VERSION ""

NS_ :

BS_:

BU_: VCU INV BMS ABS HVAC IVI GW

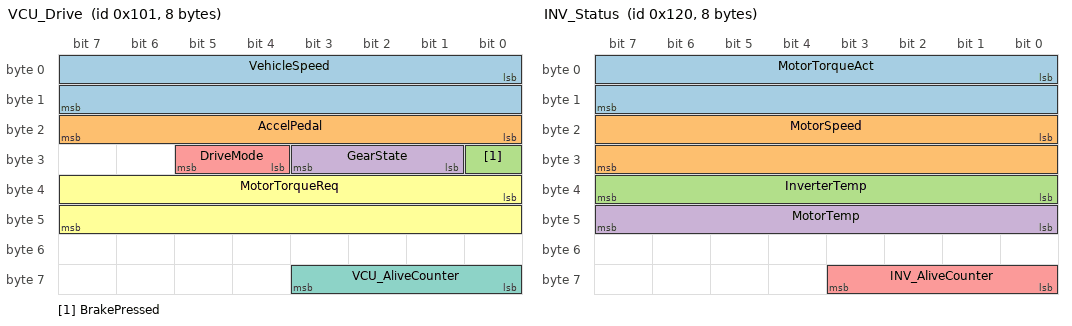
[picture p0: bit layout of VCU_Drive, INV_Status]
BO_ 257 VCU_Drive: 8 VCU
 SG_ VehicleSpeed : 0|16@1+ (0.01,0) [0|300] "km/h" GW,IVI
 SG_ AccelPedal : 16|8@1+ (0.4,0) [0|100] "%" GW
 SG_ BrakePressed : 24|1@1+ (1,0) [0|1] "" GW
 SG_ GearState : 25|3@1+ (1,0) [0|3] "" GW,IVI
 SG_ DriveMode : 28|2@1+ (1,0) [0|3] "" GW
 SG_ MotorTorqueReq : 32|16@1- (0.1,0) [-1000|1000] "Nm" INV
 SG_ VCU_AliveCounter : 56|4@1+ (1,0) [0|15] "" GW

BO_ 288 INV_Status: 8 INV
 SG_ MotorTorqueAct : 0|16@1- (0.1,0) [-1000|1000] "Nm" VCU
 SG_ MotorSpeed : 16|16@1- (1,0) [-20000|20000] "rpm" VCU
 SG_ InverterTemp : 32|8@1+ (1,-40) [-40|150] "degC" VCU
 SG_ MotorTemp : 40|8@1+ (1,-40) [-40|180] "degC" VCU
 SG_ INV_AliveCounter : 56|4@1+ (1,0) [0|15] "" VCU

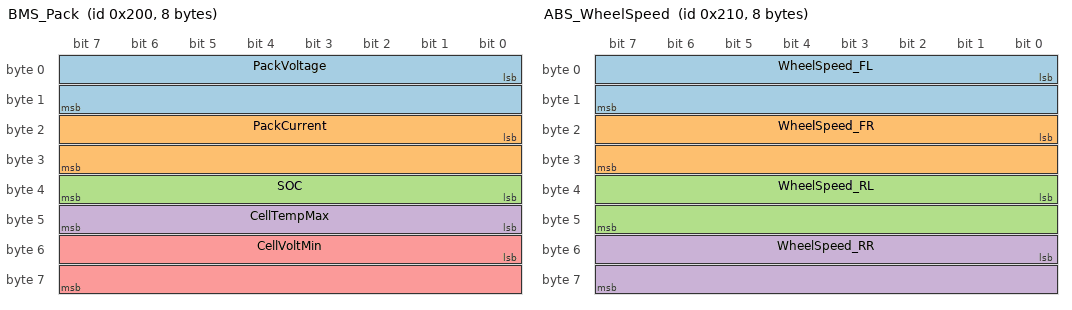
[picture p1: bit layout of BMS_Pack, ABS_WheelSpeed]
BO_ 512 BMS_Pack: 8 BMS
 SG_ PackVoltage : 0|16@1+ (0.1,0) [0|1000] "V" VCU
 SG_ PackCurrent : 16|16@1- (0.1,0) [-1500|1500] "A" VCU
 SG_ SOC : 32|8@1+ (0.5,0) [0|100] "%" VCU,IVI
 SG_ CellTempMax : 40|8@1+ (1,-40) [-40|100] "degC" VCU
 SG_ CellVoltMin : 48|16@1+ (0.001,0) [0|5] "V" VCU

BO_ 528 ABS_WheelSpeed: 8 ABS
 SG_ WheelSpeed_FL : 0|16@1+ (0.01,0) [0|300] "km/h" VCU
 SG_ WheelSpeed_FR : 16|16@1+ (0.01,0) [0|300] "km/h" VCU
 SG_ WheelSpeed_RL : 32|16@1+ (0.01,0) [0|300] "km/h" VCU
 SG_ WheelSpeed_RR : 48|16@1+ (0.01,0) [0|300] "km/h" VCU

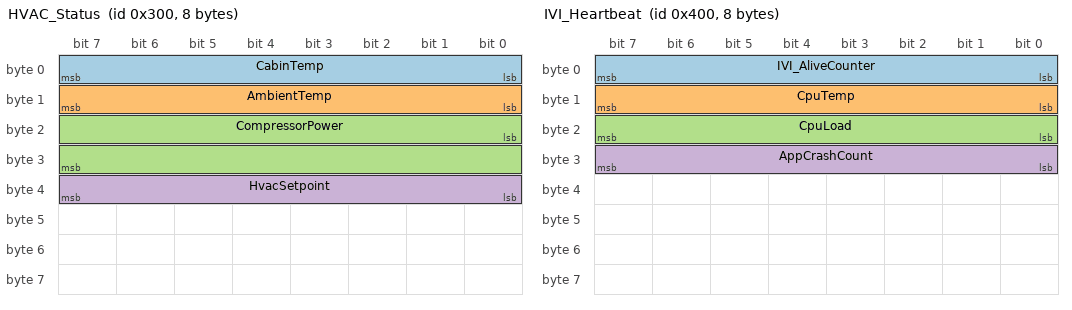
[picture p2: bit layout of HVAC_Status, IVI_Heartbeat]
BO_ 768 HVAC_Status: 8 HVAC
 SG_ CabinTemp : 0|8@1+ (0.5,-40) [-40|87.5] "degC" IVI
 SG_ AmbientTemp : 8|8@1+ (0.5,-40) [-40|87.5] "degC" IVI,VCU
 SG_ CompressorPower : 16|16@1+ (1,0) [0|10000] "W" VCU
 SG_ HvacSetpoint : 32|8@1+ (0.5,0) [0|40] "degC" IVI

BO_ 1024 IVI_Heartbeat: 8 IVI
 SG_ IVI_AliveCounter : 0|8@1+ (1,0) [0|255] "" GW
 SG_ CpuTemp : 8|8@1+ (1,-40) [-40|150] "degC" GW
 SG_ CpuLoad : 16|8@1+ (0.5,0) [0|100] "%" GW
 SG_ AppCrashCount : 24|8@1+ (1,0) [0|255] "" GW

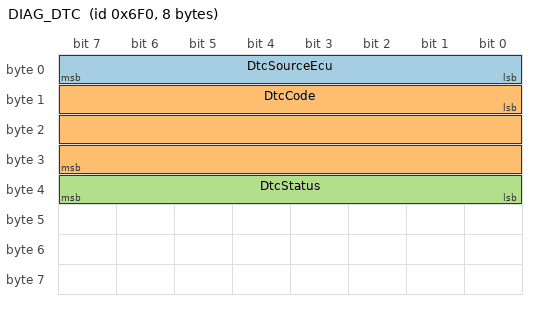
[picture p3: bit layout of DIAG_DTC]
BO_ 1776 DIAG_DTC: 8 GW
 SG_ DtcSourceEcu : 0|8@1+ (1,0) [0|255] "" Vector__XXX
 SG_ DtcCode : 8|24@1+ (1,0) [0|16777215] "" Vector__XXX
 SG_ DtcStatus : 32|8@1+ (1,0) [0|255] "" Vector__XXX

CM_ BO_ 257 "Vehicle control unit drive state broadcast";
CM_ BO_ 288 "Traction inverter status";
CM_ BO_ 512 "High-voltage battery pack summary";
CM_ BO_ 528 "Wheel speed sensors from the brake controller";
CM_ BO_ 768 "Climate control status";
CM_ BO_ 1024 "Infotainment head unit heartbeat";
CM_ BO_ 1776 "Gateway diagnostic trouble code broadcast (event driven)";
CM_ SG_ 257 VehicleSpeed "Reference vehicle speed";
CM_ SG_ 257 GearState "Selected gear";
CM_ SG_ 512 PackCurrent "Positive = discharge";
CM_ SG_ 1024 CpuLoad "Average application processor load";

BA_DEF_ BO_ "GenMsgCycleTime" INT 0 65535;
BA_DEF_DEF_ "GenMsgCycleTime" 0;
BA_ "GenMsgCycleTime" BO_ 257 50;
BA_ "GenMsgCycleTime" BO_ 288 50;
BA_ "GenMsgCycleTime" BO_ 512 100;
BA_ "GenMsgCycleTime" BO_ 528 50;
BA_ "GenMsgCycleTime" BO_ 768 500;
BA_ "GenMsgCycleTime" BO_ 1024 1000;

VAL_ 257 GearState 0 "P" 1 "R" 2 "N" 3 "D" ;
VAL_ 257 DriveMode 0 "Comfort" 1 "Sport" 2 "Eco" 3 "Reserved" ;
VAL_ 1776 DtcSourceEcu 1 "VCU" 2 "INV" 3 "BMS" 4 "HVAC" 5 "IVI" 6 "ABS" ;
